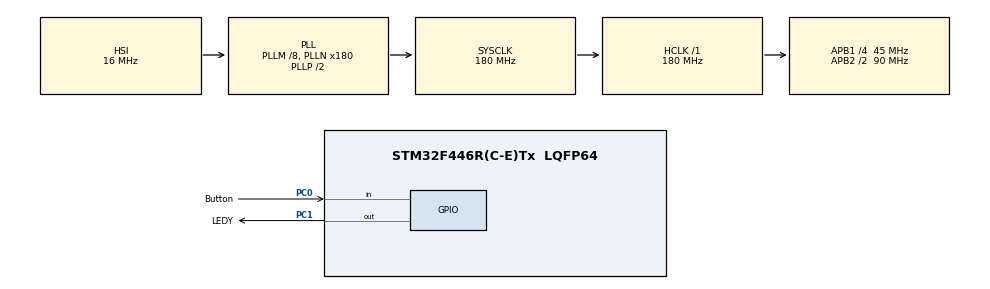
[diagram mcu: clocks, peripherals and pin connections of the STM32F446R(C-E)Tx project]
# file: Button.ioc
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Mcu.Family=STM32F4
Mcu.Name=STM32F446R(C-E)Tx
Mcu.Package=LQFP64
NVIC.PriorityGroup=NVIC_PRIORITYGROUP_4
PA13.Mode=Serial_Wire
PA13.Signal=SYS_JTMS-SWDIO
PA14.Mode=Serial_Wire
PA14.Signal=SYS_JTCK-SWCLK
PC0.GPIO_Label=Button
PC0.GPIO_PuPd=GPIO_PULLUP
PC0.Signal=GPIO_Input
PC1.GPIO_Label=LEDY
PC1.Signal=GPIO_Output
PH0-OSC_IN.Mode=HSE-External-Oscillator
PH0-OSC_IN.Signal=RCC_OSC_IN
PH1-OSC_OUT.Mode=HSE-External-Oscillator
PH1-OSC_OUT.Signal=RCC_OSC_OUT
ProjectManager.HeapSize=0x200
ProjectManager.StackSize=0x400
ProjectManager.TargetToolchain=STM32CubeIDE
RCC.AHBFreq_Value=180000000
RCC.APB1CLKDivider=RCC_HCLK_DIV4
RCC.APB1Freq_Value=45000000
RCC.APB1TimFreq_Value=90000000
RCC.APB2CLKDivider=RCC_HCLK_DIV2
RCC.APB2Freq_Value=90000000
RCC.APB2TimFreq_Value=180000000
RCC.CortexFreq_Value=180000000
RCC.HCLKFreq_Value=180000000
RCC.PLLM=8
RCC.PLLN=180
RCC.SYSCLKFreq_VALUE=180000000
RCC.SYSCLKSource=RCC_SYSCLKSOURCE_PLLCLK
RCC.USBFreq_Value=180000000
RCC.VCOOutputFreq_Value=360000000
board=custom

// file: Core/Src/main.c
/* USER CODE BEGIN Header */
/**
  ******************************************************************************
  * @file           : main.c
  * @brief          : Main program body
  ******************************************************************************
  * @attention
  *
  * Copyright (c) 2026 STMicroelectronics.
  * All rights reserved.
  *
  * This software is licensed under terms that can be found in the LICENSE file
  * in the root directory of this software component.
  * If no LICENSE file comes with this software, it is provided AS-IS.
  *
  ******************************************************************************
  */
/* USER CODE END Header */
#include "main.h"

/* USER CODE BEGIN Includes */
#include "button.h"
#include "led.h"
/* USER CODE END Includes */

/* USER CODE BEGIN PD */
// #define DEBOUNCE_MS 15
// #define LONG_PRESS_MS 500
// #define DOUBLE_CLICK_WINDOW_MS 400
// #define BLINK_INTERVAL_MS   150
// #define BLINK_BURST_TOGGLES 6
/* USER CODE END PD */

/* USER CODE BEGIN PV */
// Button Handle PV
// uint8_t button_current = 1; // 0 = Click - 1 = Unclick
// uint8_t button_last = 1;
// uint8_t button_filter = 1;
// uint8_t is_debouncing = 0;
// uint32_t time_debounce = 0;

// uint32_t time_press_start = 0;
// uint8_t  click_count      = 0;
// uint32_t time_first_click = 0;
// uint8_t is_holding = 0;
// uint8_t event_single_click = 0;
// uint8_t event_double_click = 0;

// //LED Handle PV
// uint8_t  burst_remaining = 0;
// uint32_t time_last_burst = 0;
// uint32_t time_last_blink = 0;
// static uint8_t was_holding = 0;

/* USER CODE END PV */

void SystemClock_Config(void);
static void MX_GPIO_Init(void);

/* USER CODE BEGIN 0 */
// void button_handle(void)
// {
//   // --- Debounce ---
//   uint8_t button_state = HAL_GPIO_ReadPin(Button_GPIO_Port, Button_Pin);
//   if(button_state != button_filter)
//   {
//     button_filter = button_state;
//     is_debouncing = 1;
//     time_debounce = HAL_GetTick();
//   }

//   if(is_debouncing && (HAL_GetTick()-time_debounce) >= DEBOUNCE_MS)
//   {
//     button_current = button_filter;
//     is_debouncing = 0;
//   }

//   // --- Click and Unclick ---
//   if(button_current != button_last)
//   {
//     if(button_current == 0)
//     {
//       time_press_start = HAL_GetTick();
//     }
//     else if(is_holding) // Check if holding
//     {
//       is_holding = 0;
//     }
//     else // check if double click
//     {
//       if(click_count == 0)
//       {
//         click_count = 1;
//         time_first_click = HAL_GetTick();
//       }
//       else
//       {
//         click_count = 0;
//         event_double_click = 1;
//       }
//     }
//     button_last = button_current;
//   }

//   // --- Holding ---
//   if(button_current == 0 && !is_holding && (HAL_GetTick() - time_press_start >= LONG_PRESS_MS))
//   {
//     is_holding = 1;
//     click_count = 0;
//   }

//   if(click_count == 1 && (HAL_GetTick() - time_first_click > DOUBLE_CLICK_WINDOW_MS))
//   {
//     click_count = 0;
//     event_single_click = 1;
//   }
// }

// void led_handle(void)
// {
//   // One Click
//   if(event_single_click)
//   {
//     event_single_click = 0;
//     HAL_GPIO_TogglePin(LEDY_GPIO_Port, LEDY_Pin);
//   }

//   // Double click
//   if(event_double_click)
//   {
//     event_double_click = 0;
//     burst_remaining = BLINK_BURST_TOGGLES;
//     time_last_burst = HAL_GetTick();
//   }
//   if(burst_remaining > 0 &&  (HAL_GetTick()-time_last_burst) >= BLINK_INTERVAL_MS)
//   {
//     HAL_GPIO_TogglePin(LEDY_GPIO_Port, LEDY_Pin);
//     time_last_burst = HAL_GetTick();
//     burst_remaining--;
//   }

//   // Hold
//   if(is_holding)
//   {
//     if((HAL_GetTick()-time_last_blink) >= BLINK_INTERVAL_MS)
//     {
//       HAL_GPIO_TogglePin(LEDY_GPIO_Port, LEDY_Pin);
//       time_last_blink = HAL_GetTick();
//     }
//   }
//   else if(was_holding)
//   {
//     HAL_GPIO_WritePin(LEDY_GPIO_Port, LEDY_Pin, GPIO_PIN_RESET);
//   }
//   was_holding = is_holding;
// }
/* USER CODE END 0 */

int main(void)
{

  /* MCU Configuration--------------------------------------------------------*/

  /* Reset of all peripherals, Initializes the Flash interface and the Systick. */
  HAL_Init();

  /* Configure the system clock */
  SystemClock_Config();

  /* Initialize all configured peripherals */
  MX_GPIO_Init();

  /* Infinite loop */
  while (1)
  {

    /* USER CODE BEGIN 3 */
    Button_Handle();
    LED_Handle();
  }
  /* USER CODE END 3 */
}

void SystemClock_Config(void)
{
  RCC_OscInitTypeDef RCC_OscInitStruct = {0};
  RCC_ClkInitTypeDef RCC_ClkInitStruct = {0};

  /** Configure the main internal regulator output voltage
  */
  __HAL_RCC_PWR_CLK_ENABLE();
  __HAL_PWR_VOLTAGESCALING_CONFIG(PWR_REGULATOR_VOLTAGE_SCALE1);

  /** Initializes the RCC Oscillators according to the specified parameters
  * in the RCC_OscInitTypeDef structure.
  */
  RCC_OscInitStruct.OscillatorType = RCC_OSCILLATORTYPE_HSI;
  RCC_OscInitStruct.HSIState = RCC_HSI_ON;
  RCC_OscInitStruct.HSICalibrationValue = RCC_HSICALIBRATION_DEFAULT;
  RCC_OscInitStruct.PLL.PLLState = RCC_PLL_ON;
  RCC_OscInitStruct.PLL.PLLSource = RCC_PLLSOURCE_HSI;
  RCC_OscInitStruct.PLL.PLLM = 8;
  RCC_OscInitStruct.PLL.PLLN = 180;
  RCC_OscInitStruct.PLL.PLLP = RCC_PLLP_DIV2;
  RCC_OscInitStruct.PLL.PLLQ = 2;
  RCC_OscInitStruct.PLL.PLLR = 2;
  if (HAL_RCC_OscConfig(&RCC_OscInitStruct) != HAL_OK)
  {
    Error_Handler();
  }

  /** Activate the Over-Drive mode
  */
  if (HAL_PWREx_EnableOverDrive() != HAL_OK)
  {
    Error_Handler();
  }

  /** Initializes the CPU, AHB and APB buses clocks
  */
  RCC_ClkInitStruct.ClockType = RCC_CLOCKTYPE_HCLK|RCC_CLOCKTYPE_SYSCLK
                              |RCC_CLOCKTYPE_PCLK1|RCC_CLOCKTYPE_PCLK2;
  RCC_ClkInitStruct.SYSCLKSource = RCC_SYSCLKSOURCE_PLLCLK;
  RCC_ClkInitStruct.AHBCLKDivider = RCC_SYSCLK_DIV1;
  RCC_ClkInitStruct.APB1CLKDivider = RCC_HCLK_DIV4;
  RCC_ClkInitStruct.APB2CLKDivider = RCC_HCLK_DIV2;

  if (HAL_RCC_ClockConfig(&RCC_ClkInitStruct, FLASH_LATENCY_5) != HAL_OK)
  {
    Error_Handler();
  }
}

static void MX_GPIO_Init(void)
{
  GPIO_InitTypeDef GPIO_InitStruct = {0};

  /* GPIO Ports Clock Enable */
  __HAL_RCC_GPIOH_CLK_ENABLE();
  __HAL_RCC_GPIOC_CLK_ENABLE();
  __HAL_RCC_GPIOA_CLK_ENABLE();

  /*Configure GPIO pin Output Level */
  HAL_GPIO_WritePin(LEDY_GPIO_Port, LEDY_Pin, GPIO_PIN_RESET);

  /*Configure GPIO pin : Button_Pin */
  GPIO_InitStruct.Pin = Button_Pin;
  GPIO_InitStruct.Mode = GPIO_MODE_INPUT;
  GPIO_InitStruct.Pull = GPIO_PULLUP;
  HAL_GPIO_Init(Button_GPIO_Port, &GPIO_InitStruct);

  /*Configure GPIO pin : LEDY_Pin */
  GPIO_InitStruct.Pin = LEDY_Pin;
  GPIO_InitStruct.Mode = GPIO_MODE_OUTPUT_PP;
  GPIO_InitStruct.Pull = GPIO_NOPULL;
  GPIO_InitStruct.Speed = GPIO_SPEED_FREQ_LOW;
  HAL_GPIO_Init(LEDY_GPIO_Port, &GPIO_InitStruct);

}

void Error_Handler(void)
{
  __disable_irq();
  while (1)
  {
  }
}
